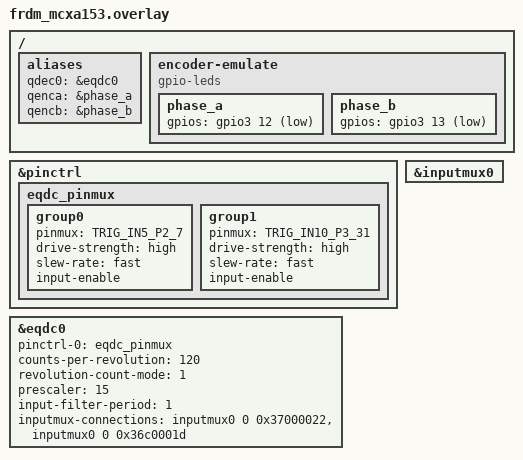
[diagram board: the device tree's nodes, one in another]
/*
 * SPDX-FileCopyrightText: 2026 NXP
 *
 * SPDX-License-Identifier: Apache-2.0
 */

/ {
	aliases {
		qdec0 = &eqdc0;
		qenca = &phase_a;
		qencb = &phase_b;
	};

	encoder-emulate {
		compatible = "gpio-leds";

		phase_a: phase_a {
			gpios = <&gpio3 12 GPIO_ACTIVE_LOW>;
		};

		phase_b: phase_b {
			gpios = <&gpio3 13 GPIO_ACTIVE_LOW>;
		};
	};
};

/* J1-12 ---> J3-3 (EQDC PHASEA)
 * J1-14 ---> J3-1 (EQDC PHASEB)
 */
&pinctrl {
	eqdc_pinmux: eqdc_pinmux {
		group0 {
			pinmux = <TRIG_IN5_P2_7>;
			drive-strength = "high";
			slew-rate = "fast";
			input-enable;
		};

		group1 {
			pinmux = <TRIG_IN10_P3_31>;
			drive-strength = "high";
			slew-rate = "fast";
			input-enable;
		};
	};
};

&inputmux0 {
	status = "okay";
};

&eqdc0 {
	status = "okay";
	pinctrl-0 = <&eqdc_pinmux>;
	pinctrl-names = "default";
	counts-per-revolution = <120>;
	revolution-count-mode = <1>;
	prescaler = <15>;
	input-filter-period = <1>;
	inputmux-connections = <&inputmux0 0 0x37000022>,
			       <&inputmux0 0 0x36c0001d>;
};
